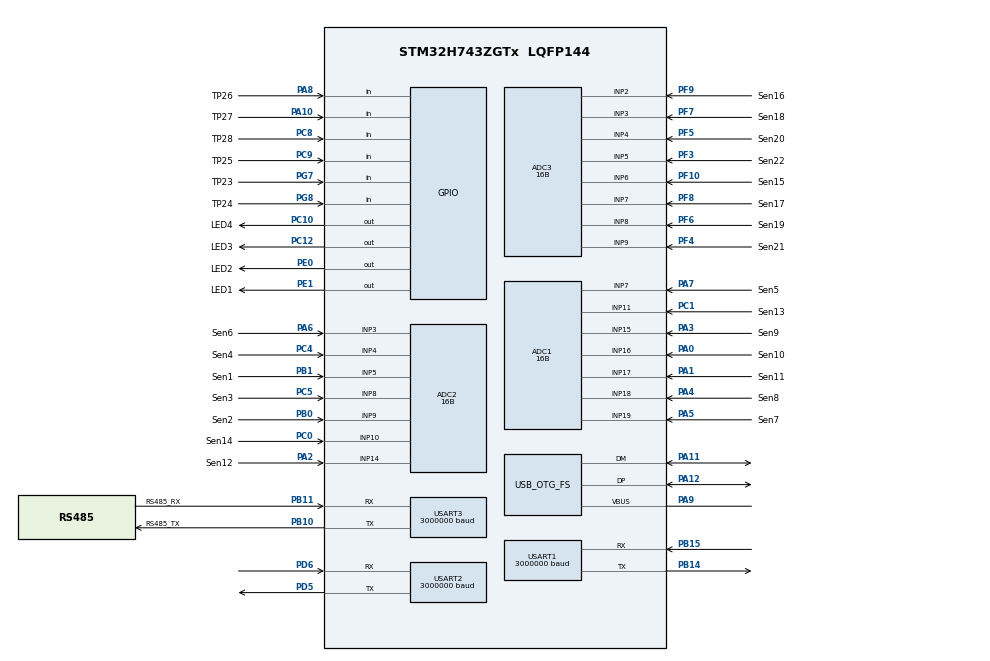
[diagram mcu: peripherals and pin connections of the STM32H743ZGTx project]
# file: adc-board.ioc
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ADC1.Channel-0\#ChannelRegularConversion=ADC_CHANNEL_7
ADC1.Channel-1\#ChannelRegularConversion=ADC_CHANNEL_11
ADC1.Channel-2\#ChannelRegularConversion=ADC_CHANNEL_15
ADC1.Channel-3\#ChannelRegularConversion=ADC_CHANNEL_16
ADC1.Channel-4\#ChannelRegularConversion=ADC_CHANNEL_17
ADC1.Channel-5\#ChannelRegularConversion=ADC_CHANNEL_18
ADC1.Channel-6\#ChannelRegularConversion=ADC_CHANNEL_19
ADC1.ClockPrescaler=ADC_CLOCK_ASYNC_DIV1
ADC1.ContinuousConvMode=DISABLE
ADC1.ConversionDataManagement=ADC_CONVERSIONDATA_DMA_CIRCULAR
ADC1.EOCSelection=ADC_EOC_SEQ_CONV
ADC1.ExternalTrigConv=ADC_EXTERNALTRIG_T1_CC1
ADC1.NbrOfConversion=7
ADC1.NbrOfConversionFlag=1
ADC1.OffsetNumber-0\#ChannelRegularConversion=ADC_OFFSET_NONE
ADC1.OffsetNumber-1\#ChannelRegularConversion=ADC_OFFSET_NONE
ADC1.OffsetNumber-2\#ChannelRegularConversion=ADC_OFFSET_NONE
ADC1.OffsetNumber-3\#ChannelRegularConversion=ADC_OFFSET_NONE
ADC1.OffsetNumber-4\#ChannelRegularConversion=ADC_OFFSET_NONE
ADC1.OffsetNumber-5\#ChannelRegularConversion=ADC_OFFSET_NONE
ADC1.OffsetNumber-6\#ChannelRegularConversion=ADC_OFFSET_NONE
ADC1.OffsetSignedSaturation-0\#ChannelRegularConversion=DISABLE
ADC1.OffsetSignedSaturation-1\#ChannelRegularConversion=DISABLE
ADC1.OffsetSignedSaturation-2\#ChannelRegularConversion=DISABLE
ADC1.OffsetSignedSaturation-3\#ChannelRegularConversion=DISABLE
ADC1.OffsetSignedSaturation-4\#ChannelRegularConversion=DISABLE
ADC1.OffsetSignedSaturation-5\#ChannelRegularConversion=DISABLE
ADC1.OffsetSignedSaturation-6\#ChannelRegularConversion=DISABLE
ADC1.Rank-0\#ChannelRegularConversion=1
ADC1.Rank-1\#ChannelRegularConversion=2
ADC1.Rank-2\#ChannelRegularConversion=3
ADC1.Rank-3\#ChannelRegularConversion=4
ADC1.Rank-4\#ChannelRegularConversion=5
ADC1.Rank-5\#ChannelRegularConversion=6
ADC1.Rank-6\#ChannelRegularConversion=7
ADC1.Resolution=ADC_RESOLUTION_16B
ADC1.SamplingTime-0\#ChannelRegularConversion=ADC_SAMPLETIME_32CYCLES_5
ADC1.SamplingTime-1\#ChannelRegularConversion=ADC_SAMPLETIME_32CYCLES_5
ADC1.SamplingTime-2\#ChannelRegularConversion=ADC_SAMPLETIME_32CYCLES_5
ADC1.SamplingTime-3\#ChannelRegularConversion=ADC_SAMPLETIME_32CYCLES_5
ADC1.SamplingTime-4\#ChannelRegularConversion=ADC_SAMPLETIME_32CYCLES_5
ADC1.SamplingTime-5\#ChannelRegularConversion=ADC_SAMPLETIME_32CYCLES_5
ADC1.SamplingTime-6\#ChannelRegularConversion=ADC_SAMPLETIME_32CYCLES_5
ADC1.master=1
ADC2.Channel-0\#ChannelRegularConversion=ADC_CHANNEL_3
ADC2.Channel-1\#ChannelRegularConversion=ADC_CHANNEL_4
ADC2.Channel-2\#ChannelRegularConversion=ADC_CHANNEL_5
ADC2.Channel-3\#ChannelRegularConversion=ADC_CHANNEL_8
ADC2.Channel-4\#ChannelRegularConversion=ADC_CHANNEL_9
ADC2.Channel-5\#ChannelRegularConversion=ADC_CHANNEL_10
ADC2.Channel-6\#ChannelRegularConversion=ADC_CHANNEL_14
ADC2.ContinuousConvMode=DISABLE
ADC2.ConversionDataManagement=ADC_CONVERSIONDATA_DMA_CIRCULAR
ADC2.EOCSelection=ADC_EOC_SEQ_CONV
ADC2.ExternalTrigConv=ADC_EXTERNALTRIG_T1_CC2
ADC2.ExternalTrigConvEdge=ADC_EXTERNALTRIGCONVEDGE_FALLING
ADC2.NbrOfConversion=7
ADC2.NbrOfConversionFlag=1
ADC2.OffsetNumber-0\#ChannelRegularConversion=ADC_OFFSET_NONE
ADC2.OffsetNumber-1\#ChannelRegularConversion=ADC_OFFSET_NONE
ADC2.OffsetNumber-2\#ChannelRegularConversion=ADC_OFFSET_NONE
ADC2.OffsetNumber-3\#ChannelRegularConversion=ADC_OFFSET_NONE
ADC2.OffsetNumber-4\#ChannelRegularConversion=ADC_OFFSET_NONE
ADC2.OffsetNumber-5\#ChannelRegularConversion=ADC_OFFSET_NONE
ADC2.OffsetNumber-6\#ChannelRegularConversion=ADC_OFFSET_NONE
ADC2.OffsetSignedSaturation-0\#ChannelRegularConversion=DISABLE
ADC2.OffsetSignedSaturation-1\#ChannelRegularConversion=DISABLE
ADC2.OffsetSignedSaturation-2\#ChannelRegularConversion=DISABLE
ADC2.OffsetSignedSaturation-3\#ChannelRegularConversion=DISABLE
ADC2.OffsetSignedSaturation-4\#ChannelRegularConversion=DISABLE
ADC2.OffsetSignedSaturation-5\#ChannelRegularConversion=DISABLE
ADC2.OffsetSignedSaturation-6\#ChannelRegularConversion=DISABLE
ADC2.Rank-0\#ChannelRegularConversion=1
ADC2.Rank-1\#ChannelRegularConversion=2
ADC2.Rank-2\#ChannelRegularConversion=3
ADC2.Rank-3\#ChannelRegularConversion=4
ADC2.Rank-4\#ChannelRegularConversion=5
ADC2.Rank-5\#ChannelRegularConversion=6
ADC2.Rank-6\#ChannelRegularConversion=7
ADC2.Resolution=ADC_RESOLUTION_16B
ADC2.SamplingTime-0\#ChannelRegularConversion=ADC_SAMPLETIME_32CYCLES_5
ADC2.SamplingTime-1\#ChannelRegularConversion=ADC_SAMPLETIME_32CYCLES_5
ADC2.SamplingTime-2\#ChannelRegularConversion=ADC_SAMPLETIME_32CYCLES_5
ADC2.SamplingTime-3\#ChannelRegularConversion=ADC_SAMPLETIME_32CYCLES_5
ADC2.SamplingTime-4\#ChannelRegularConversion=ADC_SAMPLETIME_32CYCLES_5
ADC2.SamplingTime-5\#ChannelRegularConversion=ADC_SAMPLETIME_32CYCLES_5
ADC2.SamplingTime-6\#ChannelRegularConversion=ADC_SAMPLETIME_32CYCLES_5
ADC3.Channel-0\#ChannelRegularConversion=ADC_CHANNEL_2
ADC3.Channel-1\#ChannelRegularConversion=ADC_CHANNEL_3
ADC3.Channel-2\#ChannelRegularConversion=ADC_CHANNEL_4
ADC3.Channel-3\#ChannelRegularConversion=ADC_CHANNEL_5
ADC3.Channel-4\#ChannelRegularConversion=ADC_CHANNEL_6
ADC3.Channel-5\#ChannelRegularConversion=ADC_CHANNEL_7
ADC3.Channel-6\#ChannelRegularConversion=ADC_CHANNEL_8
ADC3.Channel-7\#ChannelRegularConversion=ADC_CHANNEL_9
ADC3.ContinuousConvMode=DISABLE
ADC3.ConversionDataManagement=ADC_CONVERSIONDATA_DMA_CIRCULAR
ADC3.EOCSelection=ADC_EOC_SEQ_CONV
ADC3.ExternalTrigConv=ADC_EXTERNALTRIG_T1_CC3
ADC3.NbrOfConversion=8
ADC3.NbrOfConversionFlag=1
ADC3.OffsetNumber-0\#ChannelRegularConversion=ADC_OFFSET_NONE
ADC3.OffsetNumber-1\#ChannelRegularConversion=ADC_OFFSET_NONE
ADC3.OffsetNumber-2\#ChannelRegularConversion=ADC_OFFSET_NONE
ADC3.OffsetNumber-3\#ChannelRegularConversion=ADC_OFFSET_NONE
ADC3.OffsetNumber-4\#ChannelRegularConversion=ADC_OFFSET_NONE
ADC3.OffsetNumber-5\#ChannelRegularConversion=ADC_OFFSET_NONE
ADC3.OffsetNumber-6\#ChannelRegularConversion=ADC_OFFSET_NONE
ADC3.OffsetNumber-7\#ChannelRegularConversion=ADC_OFFSET_NONE
ADC3.OffsetSignedSaturation-0\#ChannelRegularConversion=DISABLE
ADC3.OffsetSignedSaturation-1\#ChannelRegularConversion=DISABLE
ADC3.OffsetSignedSaturation-2\#ChannelRegularConversion=DISABLE
ADC3.OffsetSignedSaturation-3\#ChannelRegularConversion=DISABLE
ADC3.OffsetSignedSaturation-4\#ChannelRegularConversion=DISABLE
ADC3.OffsetSignedSaturation-5\#ChannelRegularConversion=DISABLE
ADC3.OffsetSignedSaturation-6\#ChannelRegularConversion=DISABLE
ADC3.OffsetSignedSaturation-7\#ChannelRegularConversion=DISABLE
ADC3.OversamplingMode=DISABLE
ADC3.Rank-0\#ChannelRegularConversion=1
ADC3.Rank-1\#ChannelRegularConversion=2
ADC3.Rank-2\#ChannelRegularConversion=3
ADC3.Rank-3\#ChannelRegularConversion=4
ADC3.Rank-4\#ChannelRegularConversion=5
ADC3.Rank-5\#ChannelRegularConversion=6
ADC3.Rank-6\#ChannelRegularConversion=7
ADC3.Rank-7\#ChannelRegularConversion=8
ADC3.Resolution=ADC_RESOLUTION_16B
ADC3.SamplingTime-0\#ChannelRegularConversion=ADC_SAMPLETIME_32CYCLES_5
ADC3.SamplingTime-1\#ChannelRegularConversion=ADC_SAMPLETIME_32CYCLES_5
ADC3.SamplingTime-2\#ChannelRegularConversion=ADC_SAMPLETIME_32CYCLES_5
ADC3.SamplingTime-3\#ChannelRegularConversion=ADC_SAMPLETIME_32CYCLES_5
ADC3.SamplingTime-4\#ChannelRegularConversion=ADC_SAMPLETIME_32CYCLES_5
ADC3.SamplingTime-5\#ChannelRegularConversion=ADC_SAMPLETIME_32CYCLES_5
ADC3.SamplingTime-6\#ChannelRegularConversion=ADC_SAMPLETIME_32CYCLES_5
ADC3.SamplingTime-7\#ChannelRegularConversion=ADC_SAMPLETIME_32CYCLES_5
CORTEX_M7.CPU_DCache=Disabled
CORTEX_M7.CPU_ICache=Enabled
Dma.ADC1.1.Direction=DMA_PERIPH_TO_MEMORY
Dma.ADC1.1.EventEnable=DISABLE
Dma.ADC1.1.FIFOMode=DMA_FIFOMODE_DISABLE
Dma.ADC1.1.Instance=DMA2_Stream0
Dma.ADC1.1.MemDataAlignment=DMA_MDATAALIGN_HALFWORD
Dma.ADC1.1.MemInc=DMA_MINC_ENABLE
Dma.ADC1.1.Mode=DMA_CIRCULAR
Dma.ADC1.1.PeriphDataAlignment=DMA_PDATAALIGN_HALFWORD
Dma.ADC1.1.PeriphInc=DMA_PINC_DISABLE
Dma.ADC1.1.Polarity=HAL_DMAMUX_REQ_GEN_RISING
Dma.ADC1.1.Priority=DMA_PRIORITY_HIGH
Dma.ADC1.1.RequestNumber=1
Dma.ADC1.1.SignalID=NONE
Dma.ADC1.1.SyncEnable=DISABLE
Dma.ADC1.1.SyncPolarity=HAL_DMAMUX_SYNC_NO_EVENT
Dma.ADC1.1.SyncRequestNumber=1
Dma.ADC1.1.SyncSignalID=NONE
Dma.ADC2.2.Direction=DMA_PERIPH_TO_MEMORY
Dma.ADC2.2.EventEnable=DISABLE
Dma.ADC2.2.FIFOMode=DMA_FIFOMODE_DISABLE
Dma.ADC2.2.Instance=DMA2_Stream1
Dma.ADC2.2.MemDataAlignment=DMA_MDATAALIGN_HALFWORD
Dma.ADC2.2.MemInc=DMA_MINC_ENABLE
Dma.ADC2.2.Mode=DMA_CIRCULAR
Dma.ADC2.2.PeriphDataAlignment=DMA_PDATAALIGN_HALFWORD
Dma.ADC2.2.PeriphInc=DMA_PINC_DISABLE
Dma.ADC2.2.Polarity=HAL_DMAMUX_REQ_GEN_RISING
Dma.ADC2.2.Priority=DMA_PRIORITY_HIGH
Dma.ADC2.2.RequestNumber=1
Dma.ADC2.2.SignalID=NONE
Dma.ADC2.2.SyncEnable=DISABLE
Dma.ADC2.2.SyncPolarity=HAL_DMAMUX_SYNC_NO_EVENT
Dma.ADC2.2.SyncRequestNumber=1
Dma.ADC2.2.SyncSignalID=NONE
Dma.ADC3.0.Direction=DMA_PERIPH_TO_MEMORY
Dma.ADC3.0.EventEnable=DISABLE
Dma.ADC3.0.FIFOMode=DMA_FIFOMODE_DISABLE
Dma.ADC3.0.Instance=DMA1_Stream0
Dma.ADC3.0.MemDataAlignment=DMA_MDATAALIGN_HALFWORD
Dma.ADC3.0.MemInc=DMA_MINC_ENABLE
Dma.ADC3.0.Mode=DMA_CIRCULAR
Dma.ADC3.0.PeriphDataAlignment=DMA_PDATAALIGN_HALFWORD
Dma.ADC3.0.PeriphInc=DMA_PINC_DISABLE
Dma.ADC3.0.Polarity=HAL_DMAMUX_REQ_GEN_RISING
Dma.ADC3.0.Priority=DMA_PRIORITY_HIGH
Dma.ADC3.0.RequestNumber=1
Dma.ADC3.0.SignalID=NONE
Dma.ADC3.0.SyncEnable=DISABLE
Dma.ADC3.0.SyncPolarity=HAL_DMAMUX_SYNC_NO_EVENT
Dma.ADC3.0.SyncRequestNumber=1
Dma.ADC3.0.SyncSignalID=NONE
Dma.Request0=ADC3
Dma.Request1=ADC1
Dma.Request2=ADC2
Dma.Request3=USART3_RX
Dma.Request4=USART3_TX
Dma.USART3_RX.3.Direction=DMA_PERIPH_TO_MEMORY
Dma.USART3_RX.3.EventEnable=DISABLE
Dma.USART3_RX.3.FIFOMode=DMA_FIFOMODE_DISABLE
Dma.USART3_RX.3.Instance=DMA1_Stream1
Dma.USART3_RX.3.MemDataAlignment=DMA_MDATAALIGN_BYTE
Dma.USART3_RX.3.MemInc=DMA_MINC_ENABLE
Dma.USART3_RX.3.Mode=DMA_CIRCULAR
Dma.USART3_RX.3.PeriphDataAlignment=DMA_PDATAALIGN_BYTE
Dma.USART3_RX.3.PeriphInc=DMA_PINC_DISABLE
Dma.USART3_RX.3.Polarity=HAL_DMAMUX_REQ_GEN_RISING
Dma.USART3_RX.3.Priority=DMA_PRIORITY_LOW
Dma.USART3_RX.3.RequestNumber=1
Dma.USART3_RX.3.SignalID=NONE
Dma.USART3_RX.3.SyncEnable=DISABLE
Dma.USART3_RX.3.SyncPolarity=HAL_DMAMUX_SYNC_NO_EVENT
Dma.USART3_RX.3.SyncRequestNumber=1
Dma.USART3_RX.3.SyncSignalID=NONE
Dma.USART3_TX.4.Direction=DMA_MEMORY_TO_PERIPH
Dma.USART3_TX.4.EventEnable=DISABLE
Dma.USART3_TX.4.FIFOMode=DMA_FIFOMODE_DISABLE
Dma.USART3_TX.4.Instance=DMA1_Stream2
Dma.USART3_TX.4.MemDataAlignment=DMA_MDATAALIGN_BYTE
Dma.USART3_TX.4.MemInc=DMA_MINC_ENABLE
Dma.USART3_TX.4.Mode=DMA_NORMAL
Dma.USART3_TX.4.PeriphDataAlignment=DMA_PDATAALIGN_BYTE
Dma.USART3_TX.4.PeriphInc=DMA_PINC_DISABLE
Dma.USART3_TX.4.Polarity=HAL_DMAMUX_REQ_GEN_RISING
Dma.USART3_TX.4.Priority=DMA_PRIORITY_MEDIUM
Dma.USART3_TX.4.RequestNumber=1
Dma.USART3_TX.4.SignalID=NONE
Dma.USART3_TX.4.SyncEnable=DISABLE
Dma.USART3_TX.4.SyncPolarity=HAL_DMAMUX_SYNC_NO_EVENT
Dma.USART3_TX.4.SyncRequestNumber=1
Dma.USART3_TX.4.SyncSignalID=NONE
Mcu.Family=STM32H7
Mcu.Name=STM32H743ZGTx
Mcu.Package=LQFP144
NVIC.DMA1_Stream0_IRQn=true\:1\:0\:true\:false\:true\:false\:true
NVIC.DMA1_Stream1_IRQn=true\:0\:0\:false\:false\:true\:false\:true
NVIC.DMA1_Stream2_IRQn=true\:0\:0\:false\:false\:true\:false\:true
NVIC.DMA2_Stream0_IRQn=true\:1\:0\:true\:false\:true\:false\:true
NVIC.DMA2_Stream1_IRQn=true\:1\:0\:true\:false\:true\:false\:true
NVIC.OTG_FS_IRQn=true\:15\:0\:true\:false\:true\:false\:true
NVIC.PriorityGroup=NVIC_PRIORITYGROUP_4
NVIC.TIM1_UP_IRQn=true\:0\:0\:false\:false\:true\:true\:true
NVIC.USART1_IRQn=true\:13\:0\:true\:false\:true\:true\:true
NVIC.USART2_IRQn=true\:14\:0\:true\:false\:true\:true\:true
NVIC.USART3_IRQn=true\:14\:0\:true\:false\:true\:true\:true
PA0.GPIO_Label=Sen10
PA0.Mode=IN16-Single-Ended
PA0.Signal=ADC1_INP16
PA1.GPIO_Label=Sen11
PA1.Mode=IN17-Single-Ended
PA1.Signal=ADC1_INP17
PA10.GPIO_Label=TP27
PA10.Signal=GPIO_Input
PA11.Mode=Device_Only
PA11.Signal=USB_OTG_FS_DM
PA12.Mode=Device_Only
PA12.Signal=USB_OTG_FS_DP
PA13\ (JTMS/SWDIO).Mode=JTAG_5_pins
PA13\ (JTMS/SWDIO).Signal=DEBUG_JTMS-SWDIO
PA14\ (JTCK/SWCLK).Mode=JTAG_5_pins
PA14\ (JTCK/SWCLK).Signal=DEBUG_JTCK-SWCLK
PA15\ (JTDI).Mode=JTAG_5_pins
PA15\ (JTDI).Signal=DEBUG_JTDI
PA2.GPIO_Label=Sen12
PA2.Signal=ADCx_INP14
PA3.GPIO_Label=Sen9
PA3.Signal=ADCx_INP15
PA4.GPIO_Label=Sen8
PA4.Signal=ADCx_INP18
PA5.GPIO_Label=Sen7
PA5.Signal=ADCx_INP19
PA6.GPIO_Label=Sen6
PA6.Signal=ADCx_INP3
PA7.GPIO_Label=Sen5
PA7.Signal=ADCx_INP7
PA8.GPIO_Label=TP26
PA8.Signal=GPIO_Input
PA9.Mode=Activate_VBUS
PA9.Signal=USB_OTG_FS_VBUS
PB0.GPIO_Label=Sen2
PB0.Signal=ADCx_INP9
PB1.GPIO_Label=Sen1
PB1.Signal=ADCx_INP5
PB10.GPIO_Label=RS485_TX
PB10.Mode=Asynchronous
PB10.Signal=USART3_TX
PB11.GPIO_Label=RS485_RX
PB11.Mode=Asynchronous
PB11.Signal=USART3_RX
PB14.Mode=Asynchronous
PB14.Signal=USART1_TX
PB15.Mode=Asynchronous
PB15.Signal=USART1_RX
PB3\ (JTDO/TRACESWO).Mode=JTAG_5_pins
PB3\ (JTDO/TRACESWO).Signal=DEBUG_JTDO-SWO
PB4\ (NJTRST).Mode=JTAG_5_pins
PB4\ (NJTRST).Signal=DEBUG_JTRST
PC0.GPIO_Label=Sen14
PC0.Signal=ADCx_INP10
PC1.GPIO_Label=Sen13
PC1.Signal=ADCx_INP11
PC10.GPIO_Label=LED4
PC10.PinState=GPIO_PIN_SET
PC10.Signal=GPIO_Output
PC12.GPIO_Label=LED3
PC12.Signal=GPIO_Output
PC4.GPIO_Label=Sen4
PC4.Signal=ADCx_INP4
PC5.GPIO_Label=Sen3
PC5.Signal=ADCx_INP8
PC8.GPIO_Label=TP28
PC8.Signal=GPIO_Input
PC9.GPIO_Label=TP25
PC9.Signal=GPIO_Input
PD5.Mode=Asynchronous
PD5.Signal=USART2_TX
PD6.Mode=Asynchronous
PD6.Signal=USART2_RX
PE0.GPIO_Label=LED2
PE0.Signal=GPIO_Output
PE1.GPIO_Label=LED1
PE1.Signal=GPIO_Output
PF10.GPIO_Label=Sen15
PF10.Mode=IN6-Single-Ended
PF10.Signal=ADC3_INP6
PF3.GPIO_Label=Sen22
PF3.Mode=IN5-Single-Ended
PF3.Signal=ADC3_INP5
PF4.GPIO_Label=Sen21
PF4.Mode=IN9-Single-Ended
PF4.Signal=ADC3_INP9
PF5.GPIO_Label=Sen20
PF5.Mode=IN4-Single-Ended
PF5.Signal=ADC3_INP4
PF6.GPIO_Label=Sen19
PF6.Mode=IN8-Single-Ended
PF6.Signal=ADC3_INP8
PF7.GPIO_Label=Sen18
PF7.Mode=IN3-Single-Ended
PF7.Signal=ADC3_INP3
PF8.GPIO_Label=Sen17
PF8.Mode=IN7-Single-Ended
PF8.Signal=ADC3_INP7
PF9.GPIO_Label=Sen16
PF9.Mode=IN2-Single-Ended
PF9.Signal=ADC3_INP2
PG7.GPIO_Label=TP23
PG7.Signal=GPIO_Input
PG8.GPIO_Label=TP24
PG8.Signal=GPIO_Input
ProjectManager.HeapSize=0x200
ProjectManager.StackSize=0x400
ProjectManager.TargetToolchain=STM32CubeIDE
RCC.ADCFreq_Value=120000000
RCC.APB1Freq_Value=120000000
RCC.APB2Freq_Value=120000000
RCC.APB3Freq_Value=120000000
RCC.APB4Freq_Value=120000000
RCC.CortexFreq_Value=60000000
RCC.Cortex_Div=SYSTICK_CLKSOURCE_HCLK_DIV8
RCC.D1PPRE=RCC_APB3_DIV2
RCC.D2PPRE1=RCC_APB1_DIV2
RCC.D2PPRE2=RCC_APB2_DIV2
RCC.D3PPRE=RCC_APB4_DIV2
RCC.DIVM1=8
RCC.DIVM2=4
RCC.DIVM3=4
RCC.DIVN1=120
RCC.DIVN2=30
RCC.DIVN3=48
RCC.DIVP2=4
RCC.DIVQ1=5
RCC.DIVQ2=16
RCC.DIVQ3=8
RCC.DIVR3=6
RCC.HCLKFreq_Value=240000000
RCC.HPRE=RCC_HCLK_DIV2
RCC.HSE_VALUE=8000000
RCC.PLL2FRACN=0
RCC.PLLFRACN=0
RCC.SYSCLKFreq_VALUE=480000000
RCC.SYSCLKSource=RCC_SYSCLKSOURCE_PLLCLK
RCC.USART16CLockSelection=RCC_USART16CLKSOURCE_PLL3
RCC.USART234578CLockSelection=RCC_USART234578CLKSOURCE_PLL3
RCC.USBCLockSelection=RCC_USBCLKSOURCE_HSI48
RCC.USBFreq_Value=48000000
SH.ADCx_INP10.0=ADC2_INP10,IN10-Single-Ended
SH.ADCx_INP11.0=ADC1_INP11,IN11-Single-Ended
SH.ADCx_INP14.0=ADC2_INP14,IN14-Single-Ended
SH.ADCx_INP15.0=ADC1_INP15,IN15-Single-Ended
SH.ADCx_INP18.0=ADC1_INP18,IN18-Single-Ended
SH.ADCx_INP19.0=ADC1_INP19,IN19-Single-Ended
SH.ADCx_INP3.0=ADC2_INP3,IN3-Single-Ended
SH.ADCx_INP4.0=ADC2_INP4,IN4-Single-Ended
SH.ADCx_INP5.0=ADC2_INP5,IN5-Single-Ended
SH.ADCx_INP7.0=ADC1_INP7,IN7-Single-Ended
SH.ADCx_INP8.0=ADC2_INP8,IN8-Single-Ended
SH.ADCx_INP9.0=ADC2_INP9,IN9-Single-Ended
TIM1.AutoReloadPreload=TIM_AUTORELOAD_PRELOAD_ENABLE
TIM1.Channel-Output\ Compare4\ No\ Output=TIM_CHANNEL_4
TIM1.Channel-PWM\ Generation1\ No\ Output=TIM_CHANNEL_1
TIM1.Channel-PWM\ Generation2\ No\ Output=TIM_CHANNEL_2
TIM1.Channel-PWM\ Generation3\ No\ Output=TIM_CHANNEL_3
TIM1.Period=5999
TIM1.Prescaler=1
TIM1.Pulse-Output\ Compare4\ No\ Output=0
TIM1.Pulse-PWM\ Generation1\ No\ Output=1
TIM1.Pulse-PWM\ Generation2\ No\ Output=2000
TIM1.Pulse-PWM\ Generation3\ No\ Output=4000
TIM1.TIM_MasterOutputTrigger=TIM_TRGO_OC4REF
TIM1.TIM_MasterOutputTrigger2=TIM_TRGO2_RESET
USART1.BaudRate=3000000
USART1.FIFOMode=FIFOMODE_ENABLE
USART1.VirtualMode-Asynchronous=VM_ASYNC
USART2.BaudRate=3000000
USART2.FIFOMode=FIFOMODE_ENABLE
USART2.VirtualMode-Asynchronous=VM_ASYNC
USART3.BaudRate=3000000
USART3.FIFOMode=FIFOMODE_ENABLE
USART3.VirtualMode-Asynchronous=VM_ASYNC
USB_DEVICE.CLASS_NAME_FS=CDC
USB_DEVICE.VirtualMode-CDC_FS=Cdc
USB_DEVICE.VirtualModeFS=Cdc_FS
USB_OTG_FS.VirtualMode=Device_Only
USB_OTG_FS.battery_charging_enable=DISABLE
VP_RCC_USB.Mode=USB_FS
VP_TIM1_VS_ClockSourceINT.Mode=Internal
VP_TIM1_VS_no_output1.Mode=PWM Generation1 No Output
VP_TIM1_VS_no_output2.Mode=PWM Generation2 No Output
VP_TIM1_VS_no_output3.Mode=PWM Generation3 No Output
VP_TIM1_VS_no_output4.Mode=Output Compare4 No Output
VP_USB_DEVICE_VS_USB_DEVICE_CDC_FS.Mode=CDC_FS
VP_VREFBUF_V_VREFBUF.Mode=ExternalMode
board=custom

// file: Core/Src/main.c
/* USER CODE BEGIN Header */
/**
  ******************************************************************************
  * @file           : main.c
  * @brief          : Main program body
  ******************************************************************************
  * @attention
  *
  * <h2><center>&copy; Copyright (c) 2020 STMicroelectronics.
  * All rights reserved.</center></h2>
  *
  * This software component is licensed by ST under Ultimate Liberty license
  * SLA0044, the "License"; You may not use this file except in compliance with
  * the License. You may obtain a copy of the License at:
  *                             www.st.com/SLA0044
  *
  ******************************************************************************
  */
/* USER CODE END Header */
#include "main.h"
#include "usb_device.h"

/* USER CODE BEGIN Includes */
//#include "usbd_cdc_if.h"
#include "hdlc.h"
/* USER CODE END Includes */

ADC_HandleTypeDef hadc1;
ADC_HandleTypeDef hadc2;
ADC_HandleTypeDef hadc3;
DMA_HandleTypeDef hdma_adc1;
DMA_HandleTypeDef hdma_adc2;
DMA_HandleTypeDef hdma_adc3;

TIM_HandleTypeDef htim1;

UART_HandleTypeDef huart1;
UART_HandleTypeDef huart2;
UART_HandleTypeDef huart3;
DMA_HandleTypeDef hdma_usart3_rx;
DMA_HandleTypeDef hdma_usart3_tx;

void SystemClock_Config(void);
void PeriphCommonClock_Config(void);
static void MX_GPIO_Init(void);
static void MX_DMA_Init(void);
static void MX_ADC1_Init(void);
static void MX_ADC2_Init(void);
static void MX_ADC3_Init(void);
static void MX_USART1_UART_Init(void);
static void MX_USART3_UART_Init(void);
static void MX_USART2_UART_Init(void);
static void MX_TIM1_Init(void);

/* USER CODE BEGIN 0 */

// important stuff in here!
struct systemstatus status;

// we should compute sample_rate from the clock
// and timer configuration.
uint32_t sample_rate = 20000;

// Our DMA buffer is DMASIZE samples deep, and we don't get an interrupt
// until it is full. So when it is >1, we only run our DSP every that many
// samples. No samples are dropped! We just don't process every time.
#define DMASIZE 2

// Instruct the compiler to align these to cache-line boundaries
// They'll always be read/written as blocks, independently from
// the others, or anything else.
// We also move them into the .dmabuffers section, which is the
// only thing in RAM_D3, so as to minimize contention between
// DMA copying the ADC values into RAM, and everything else we do.
__attribute__ ((aligned (32))) __attribute__(( section(".dmabuffers") )) uint16_t adc1_buffer[7*DMASIZE];
// adc2 drops some DMAs here and there.
__attribute__ ((aligned (32))) __attribute__(( section(".dmabuffers") )) uint16_t adc2_buffer[7*DMASIZE];
__attribute__ ((aligned (32))) __attribute__(( section(".dmabuffers") )) uint16_t adc3_buffer[8*DMASIZE];

// Represents what we need to know for a sensor.
// Values in here should only be altered by external
// configuration processes.
// updates to this structure should be done as atomically
// as possible. prepare a new copy on the stack, disable
// interrupts, bcopy into this array, and reenable.
// TODO get this stored in DTCM
struct sensorconf {
	// True means we're watching a hammer; rises only
	_Bool hammer;
	// Hammer stuff
	// absolute position must be above this to trigger derivative calculations
	// that's a prereq for a note to occur. it should, ideally, be between
	// "impact" and the let off point.
	float minpos;

	// Key stick stuff
	int hammerchan; // corresponding hammer
	float offpos;     // reading at which to trip to off
} conf[22];

struct sensorstate {
	uint32_t notesent; // 0=nothing sent recently, otherwise time of send
	float sentval; // the velocity we sent.
	_Bool damperup;
	_Bool notesounding; // we've sent a noteon, and haven't yet sent a noteoff for it
} state[22];

uint16_t collectstats = 0;
struct sensorstat {
	uint16_t min;
	uint16_t max;
	uint32_t sum;
	uint32_t count;
} stats[22];

struct __attribute__((__packed__)) sensortrip {
	float velocity;
	uint8_t chan;
};

#define BUFSIZE 32
// TODO move these into DTCM
int bufferptrs[3] = { 0 }; // points to the locations we'll write to next. one past the most recent value.
float sensorbuffer[22][BUFSIZE] = { 0.0 };
float derivs[22][3] = { 0.0 } ;
int derividxs[22] = { 0 };

#define FIR_LEN 13
// TODO want this in DTCM also
// scipy.signal.savgol_coeffs(13, 2, deriv=1, use='dot', delta=0.01)
// the delta doesn't matter, so it was chosen to bring the values to ~1.0
float filter[FIR_LEN] = { -3.2967032967033107, -2.7472527472527473,
		-2.197802197802188, -1.64835164835163, -1.0989010989010746,
		-0.5494505494505213, 2.9531932455029164e-14, 0.5494505494505779,
		1.098901098901124, 1.6483516483516676, 2.1978021978022086,
		2.7472527472527473, 3.296703296703284 };
// supposedly argerich can play 11.52 notes/second
// 16000 samples per second. let's leave her some room,
// and assume 16 notes/second. 16000/16 = 1000
#define MINCYCLESBETWEENNOTES 500

_Bool update_setting(uint8_t channel, uint8_t setting, uint32_t value)
{
	if(channel<0 || channel>=22) {
		return 0;
	}
	switch(setting) {
	case 0: {
		// channel type
		if(value==0 || value==1) {
			conf[channel].hammer = value;
			return 1;
		}
		break;
	}
	case 1: {
		// hammer minpos
		float v = *((float *)&value);
		if(conf[channel].hammer && v>1.0 && v<65535.0) {
			conf[channel].minpos = v;
			return 1;
		}
		break;
	}
	case 2: {
		// damper off pos
		float v = *((float *)&value);
		if((!conf[channel].hammer) && v>1.0 && v<65535.0) {
			conf[channel].offpos = v;
			return 1;
		}
		break;
	}
	case 3: {
		// hammer channel for this dampener
		if(conf[channel].hammer)
			// channel is a hammer, not a dampener, can't set this.
			return 0;
		if(value<0 || value>=22)
			// channel out of range
			return 0;
		if(!conf[value].hammer)
			// target channel isn't a hammer!
			return 0;
		conf[channel].hammerchan = value;
		return 1;
	}
	}

	// couldn't successfully process whatever it was.
	return 0;
}

/* USER CODE END 0 */

int main(void)
{

  /* Enable I-Cache---------------------------------------------------------*/
  SCB_EnableICache();

  /* MCU Configuration--------------------------------------------------------*/

  /* Reset of all peripherals, Initializes the Flash interface and the Systick. */
  HAL_Init();

  /* Configure the system clock */
  SystemClock_Config();

/* Configure the peripherals common clocks */
  PeriphCommonClock_Config();

  /* Initialize all configured peripherals */
  MX_GPIO_Init();
  MX_DMA_Init();
  MX_ADC1_Init();
  MX_ADC2_Init();
  MX_ADC3_Init();
  MX_USART1_UART_Init();
  MX_USART3_UART_Init();
  MX_USART2_UART_Init();
  MX_USB_DEVICE_Init();
  MX_TIM1_Init();
  /* USER CODE BEGIN 2 */

  HDLC_Init(&huart3, &hdma_usart3_rx);

  // put some plausible values in the autodetection routines.
  // and get the state initialized.
  for(int i=0; i<22; i++) {
	  // hammer default
	  conf[i].minpos = 15000;

	  // keystick default
	  conf[i].offpos = 9000;

	  state[i].notesent = 0;
	  state[i].sentval = 0.0;
	  state[i].damperup = 0;
	  state[i].notesounding = 0;
  }
  // the hammers
  conf[0].hammer = 1;
  conf[1].hammer = 1;
  conf[2].hammer = 1;
  conf[4].hammer = 1;
  conf[6].hammer = 1;
  conf[9].minpos = 20000;
  conf[9].hammer = 1;
  conf[10].hammer = 1;
  conf[18].hammer = 1;
  conf[18].minpos = 12000;
  conf[19].hammer = 1;
  conf[20].hammer = 1;
  conf[21].hammer = 1;
  // key sticks
  conf[3].hammerchan = 2;
  conf[5].hammerchan = 6;
  conf[5].offpos = 5000;
  conf[7].hammerchan = 0;
  conf[7].offpos = 5000;
  conf[8].hammerchan = 10;
  conf[11].hammerchan = 9;
  conf[11].offpos = 5000;
  conf[12].hammerchan = 1;
  conf[13].hammerchan = 4;
  conf[13].offpos = 5000;
  conf[14].hammerchan = 18;
  conf[15].hammerchan = 19;
  conf[16].hammerchan = 20;
  conf[17].hammerchan = 21;

  HAL_Delay(10);
  HAL_ADCEx_Calibration_Start(&hadc1, ADC_CALIB_OFFSET, ADC_SINGLE_ENDED);
  HAL_Delay(10);
  HAL_ADCEx_Calibration_Start(&hadc2, ADC_CALIB_OFFSET, ADC_SINGLE_ENDED);
  HAL_Delay(10);
  HAL_ADCEx_Calibration_Start(&hadc3, ADC_CALIB_OFFSET, ADC_SINGLE_ENDED);
  HAL_Delay(10);

  {
	  // fill out / initialize the system status struct
	  status.uniqueid[0] = HAL_GetUIDw0();
	  status.uniqueid[1] = HAL_GetUIDw1();
	  status.uniqueid[2] = HAL_GetUIDw2();
	  status.devid = HAL_GetDEVID();
	  status.revid = HAL_GetREVID();
	  // derived this expression from the code for HAL_GetUIDw0
	  status.flashsize = READ_REG(*((uint32_t *)FLASHSIZE_BASE));

	  // this one is actually important, we use it in places
	  status.sample_time = 0;
	  status.adc1_dmas = 0;
	  status.adc2_dmas = 0;
	  status.adc3_dmas = 0;
  }

  HDLC_Send_Frame(&huart3, 0x03, "calibdone", 9);
  HDLC_Send_Frame(&huart3, 0x03, "calibdone", 9);
  HDLC_Send_Frame(&huart3, 0x03, "calibdone", 9);

  HAL_TIM_Base_Start_IT(&htim1);

  // start timer
  HAL_ADC_Start_DMA(&hadc1, (uint32_t*)adc1_buffer, 7*DMASIZE);
  HAL_ADC_Start_DMA(&hadc2, (uint32_t*)adc2_buffer, 7*DMASIZE);
  HAL_ADC_Start_DMA(&hadc3, (uint32_t*)adc3_buffer, 8*DMASIZE);
  HAL_TIM_PWM_Start(&htim1, TIM_CHANNEL_1);
  HAL_TIM_PWM_Start(&htim1, TIM_CHANNEL_2);
  HAL_TIM_PWM_Start(&htim1, TIM_CHANNEL_3);
  HAL_TIM_OC_Start(&htim1, TIM_CHANNEL_4);

  /* USER CODE END 2 */

  /* Infinite loop */
  /* USER CODE BEGIN WHILE */

  uint32_t last_clock_pulse = 1<<30;
  while (1)
  {
	  // we'll wake up occasionally.
	  __asm("wfi");

	  // how much time has passed since our last clock message?
	  // if(lots) { output new clock message }
	  uint32_t clock_rate = sample_rate * 64; // 64 seconds; should be a bitshift
	  if(  ((status.sample_time < last_clock_pulse) &&
		    ((UINT32_MAX - last_clock_pulse) + status.sample_time >= clock_rate))
		|| ((status.sample_time > last_clock_pulse) &&
			(status.sample_time - last_clock_pulse >= clock_rate)) ) {
		  // we've passed clock_rate worth of samples, so we'll send another clock message
		  HDLC_Send_Frame(&huart3, 0x07, (uint8_t*)&(status.sample_time), sizeof(uint32_t));
		  last_clock_pulse = status.sample_time;
	  }

	  if(collectstats) {
		  if((status.sample_time % collectstats)==0) {
			  // we should be collecting stats. send them out.
			  HDLC_Send_Frame(&huart3, 0x0C, (uint8_t*)stats, sizeof(stats));
			  for(int i=0; i<22; i++) {
				  stats[i].min = -1;
				  stats[i].max = 0;
				  stats[i].sum = 0;
				  stats[i].count = 0;
			  }
		  }
	  }

    /* USER CODE END WHILE */

  }
}

void SystemClock_Config(void)
{
  RCC_OscInitTypeDef RCC_OscInitStruct = {0};
  RCC_ClkInitTypeDef RCC_ClkInitStruct = {0};
  RCC_CRSInitTypeDef RCC_CRSInitStruct = {0};

  /** Supply configuration update enable
  */
  HAL_PWREx_ConfigSupply(PWR_LDO_SUPPLY);
  /** Configure the main internal regulator output voltage
  */
  __HAL_PWR_VOLTAGESCALING_CONFIG(PWR_REGULATOR_VOLTAGE_SCALE0);

  while(!__HAL_PWR_GET_FLAG(PWR_FLAG_VOSRDY)) {}
  /** Macro to configure the PLL clock source
  */
  __HAL_RCC_PLL_PLLSOURCE_CONFIG(RCC_PLLSOURCE_HSI);
  /** Initializes the RCC Oscillators according to the specified parameters
  * in the RCC_OscInitTypeDef structure.
  */
  RCC_OscInitStruct.OscillatorType = RCC_OSCILLATORTYPE_HSI48|RCC_OSCILLATORTYPE_HSI;
  RCC_OscInitStruct.HSIState = RCC_HSI_DIV1;
  RCC_OscInitStruct.HSICalibrationValue = RCC_HSICALIBRATION_DEFAULT;
  RCC_OscInitStruct.HSI48State = RCC_HSI48_ON;
  RCC_OscInitStruct.PLL.PLLState = RCC_PLL_ON;
  RCC_OscInitStruct.PLL.PLLSource = RCC_PLLSOURCE_HSI;
  RCC_OscInitStruct.PLL.PLLM = 8;
  RCC_OscInitStruct.PLL.PLLN = 120;
  RCC_OscInitStruct.PLL.PLLP = 2;
  RCC_OscInitStruct.PLL.PLLQ = 5;
  RCC_OscInitStruct.PLL.PLLR = 2;
  RCC_OscInitStruct.PLL.PLLRGE = RCC_PLL1VCIRANGE_3;
  RCC_OscInitStruct.PLL.PLLVCOSEL = RCC_PLL1VCOWIDE;
  RCC_OscInitStruct.PLL.PLLFRACN = 0;
  if (HAL_RCC_OscConfig(&RCC_OscInitStruct) != HAL_OK)
  {
    Error_Handler();
  }
  /** Initializes the CPU, AHB and APB buses clocks
  */
  RCC_ClkInitStruct.ClockType = RCC_CLOCKTYPE_HCLK|RCC_CLOCKTYPE_SYSCLK
                              |RCC_CLOCKTYPE_PCLK1|RCC_CLOCKTYPE_PCLK2
                              |RCC_CLOCKTYPE_D3PCLK1|RCC_CLOCKTYPE_D1PCLK1;
  RCC_ClkInitStruct.SYSCLKSource = RCC_SYSCLKSOURCE_PLLCLK;
  RCC_ClkInitStruct.SYSCLKDivider = RCC_SYSCLK_DIV1;
  RCC_ClkInitStruct.AHBCLKDivider = RCC_HCLK_DIV2;
  RCC_ClkInitStruct.APB3CLKDivider = RCC_APB3_DIV2;
  RCC_ClkInitStruct.APB1CLKDivider = RCC_APB1_DIV2;
  RCC_ClkInitStruct.APB2CLKDivider = RCC_APB2_DIV2;
  RCC_ClkInitStruct.APB4CLKDivider = RCC_APB4_DIV2;

  if (HAL_RCC_ClockConfig(&RCC_ClkInitStruct, FLASH_LATENCY_4) != HAL_OK)
  {
    Error_Handler();
  }
  /** Enable the SYSCFG APB clock
  */
  __HAL_RCC_CRS_CLK_ENABLE();
  /** Configures CRS
  */
  RCC_CRSInitStruct.Prescaler = RCC_CRS_SYNC_DIV1;
  RCC_CRSInitStruct.Source = RCC_CRS_SYNC_SOURCE_USB2;
  RCC_CRSInitStruct.Polarity = RCC_CRS_SYNC_POLARITY_RISING;
  RCC_CRSInitStruct.ReloadValue = __HAL_RCC_CRS_RELOADVALUE_CALCULATE(48000000,1000);
  RCC_CRSInitStruct.ErrorLimitValue = 34;
  RCC_CRSInitStruct.HSI48CalibrationValue = 32;

  HAL_RCCEx_CRSConfig(&RCC_CRSInitStruct);
}

void PeriphCommonClock_Config(void)
{
  RCC_PeriphCLKInitTypeDef PeriphClkInitStruct = {0};

  /** Initializes the peripherals clock
  */
  PeriphClkInitStruct.PeriphClockSelection = RCC_PERIPHCLK_ADC|RCC_PERIPHCLK_USART1
                              |RCC_PERIPHCLK_USART2|RCC_PERIPHCLK_USART3;
  PeriphClkInitStruct.PLL2.PLL2M = 4;
  PeriphClkInitStruct.PLL2.PLL2N = 30;
  PeriphClkInitStruct.PLL2.PLL2P = 4;
  PeriphClkInitStruct.PLL2.PLL2Q = 16;
  PeriphClkInitStruct.PLL2.PLL2R = 2;
  PeriphClkInitStruct.PLL2.PLL2RGE = RCC_PLL2VCIRANGE_3;
  PeriphClkInitStruct.PLL2.PLL2VCOSEL = RCC_PLL2VCOWIDE;
  PeriphClkInitStruct.PLL2.PLL2FRACN = 0;
  PeriphClkInitStruct.PLL3.PLL3M = 4;
  PeriphClkInitStruct.PLL3.PLL3N = 48;
  PeriphClkInitStruct.PLL3.PLL3P = 2;
  PeriphClkInitStruct.PLL3.PLL3Q = 8;
  PeriphClkInitStruct.PLL3.PLL3R = 6;
  PeriphClkInitStruct.PLL3.PLL3RGE = RCC_PLL3VCIRANGE_3;
  PeriphClkInitStruct.PLL3.PLL3VCOSEL = RCC_PLL3VCOWIDE;
  PeriphClkInitStruct.PLL3.PLL3FRACN = 0;
  PeriphClkInitStruct.Usart234578ClockSelection = RCC_USART234578CLKSOURCE_PLL3;
  PeriphClkInitStruct.Usart16ClockSelection = RCC_USART16CLKSOURCE_PLL3;
  PeriphClkInitStruct.AdcClockSelection = RCC_ADCCLKSOURCE_PLL2;
  if (HAL_RCCEx_PeriphCLKConfig(&PeriphClkInitStruct) != HAL_OK)
  {
    Error_Handler();
  }
}

static void MX_ADC1_Init(void)
{

  ADC_MultiModeTypeDef multimode = {0};
  ADC_ChannelConfTypeDef sConfig = {0};

  /** Common config
  */
  hadc1.Instance = ADC1;
  hadc1.Init.ClockPrescaler = ADC_CLOCK_ASYNC_DIV1;
  hadc1.Init.Resolution = ADC_RESOLUTION_16B;
  hadc1.Init.ScanConvMode = ADC_SCAN_ENABLE;
  hadc1.Init.EOCSelection = ADC_EOC_SEQ_CONV;
  hadc1.Init.LowPowerAutoWait = DISABLE;
  hadc1.Init.ContinuousConvMode = DISABLE;
  hadc1.Init.NbrOfConversion = 7;
  hadc1.Init.DiscontinuousConvMode = DISABLE;
  hadc1.Init.ExternalTrigConv = ADC_EXTERNALTRIG_T1_CC1;
  hadc1.Init.ExternalTrigConvEdge = ADC_EXTERNALTRIGCONVEDGE_RISING;
  hadc1.Init.ConversionDataManagement = ADC_CONVERSIONDATA_DMA_CIRCULAR;
  hadc1.Init.Overrun = ADC_OVR_DATA_PRESERVED;
  hadc1.Init.LeftBitShift = ADC_LEFTBITSHIFT_NONE;
  hadc1.Init.OversamplingMode = DISABLE;
  if (HAL_ADC_Init(&hadc1) != HAL_OK)
  {
    Error_Handler();
  }
  /** Configure the ADC multi-mode
  */
  multimode.Mode = ADC_MODE_INDEPENDENT;
  if (HAL_ADCEx_MultiModeConfigChannel(&hadc1, &multimode) != HAL_OK)
  {
    Error_Handler();
  }
  /** Configure Regular Channel
  */
  sConfig.Channel = ADC_CHANNEL_7;
  sConfig.Rank = ADC_REGULAR_RANK_1;
  sConfig.SamplingTime = ADC_SAMPLETIME_32CYCLES_5;
  sConfig.SingleDiff = ADC_SINGLE_ENDED;
  sConfig.OffsetNumber = ADC_OFFSET_NONE;
  sConfig.Offset = 0;
  sConfig.OffsetSignedSaturation = DISABLE;
  if (HAL_ADC_ConfigChannel(&hadc1, &sConfig) != HAL_OK)
  {
    Error_Handler();
  }
  /** Configure Regular Channel
  */
  sConfig.Channel = ADC_CHANNEL_11;
  sConfig.Rank = ADC_REGULAR_RANK_2;
  if (HAL_ADC_ConfigChannel(&hadc1, &sConfig) != HAL_OK)
  {
    Error_Handler();
  }
  /** Configure Regular Channel
  */
  sConfig.Channel = ADC_CHANNEL_15;
  sConfig.Rank = ADC_REGULAR_RANK_3;
  if (HAL_ADC_ConfigChannel(&hadc1, &sConfig) != HAL_OK)
  {
    Error_Handler();
  }
  /** Configure Regular Channel
  */
  sConfig.Channel = ADC_CHANNEL_16;
  sConfig.Rank = ADC_REGULAR_RANK_4;
  if (HAL_ADC_ConfigChannel(&hadc1, &sConfig) != HAL_OK)
  {
    Error_Handler();
  }
  /** Configure Regular Channel
  */
  sConfig.Channel = ADC_CHANNEL_17;
  sConfig.Rank = ADC_REGULAR_RANK_5;
  if (HAL_ADC_ConfigChannel(&hadc1, &sConfig) != HAL_OK)
  {
    Error_Handler();
  }
  /** Configure Regular Channel
  */
  sConfig.Channel = ADC_CHANNEL_18;
  sConfig.Rank = ADC_REGULAR_RANK_6;
  if (HAL_ADC_ConfigChannel(&hadc1, &sConfig) != HAL_OK)
  {
    Error_Handler();
  }
  /** Configure Regular Channel
  */
  sConfig.Channel = ADC_CHANNEL_19;
  sConfig.Rank = ADC_REGULAR_RANK_7;
  if (HAL_ADC_ConfigChannel(&hadc1, &sConfig) != HAL_OK)
  {
    Error_Handler();
  }

}

static void MX_ADC2_Init(void)
{

  ADC_ChannelConfTypeDef sConfig = {0};

  /** Common config
  */
  hadc2.Instance = ADC2;
  hadc2.Init.ClockPrescaler = ADC_CLOCK_ASYNC_DIV1;
  hadc2.Init.Resolution = ADC_RESOLUTION_16B;
  hadc2.Init.ScanConvMode = ADC_SCAN_ENABLE;
  hadc2.Init.EOCSelection = ADC_EOC_SEQ_CONV;
  hadc2.Init.LowPowerAutoWait = DISABLE;
  hadc2.Init.ContinuousConvMode = DISABLE;
  hadc2.Init.NbrOfConversion = 7;
  hadc2.Init.DiscontinuousConvMode = DISABLE;
  hadc2.Init.ExternalTrigConv = ADC_EXTERNALTRIG_T1_CC2;
  hadc2.Init.ExternalTrigConvEdge = ADC_EXTERNALTRIGCONVEDGE_FALLING;
  hadc2.Init.ConversionDataManagement = ADC_CONVERSIONDATA_DMA_CIRCULAR;
  hadc2.Init.Overrun = ADC_OVR_DATA_PRESERVED;
  hadc2.Init.LeftBitShift = ADC_LEFTBITSHIFT_NONE;
  hadc2.Init.OversamplingMode = DISABLE;
  if (HAL_ADC_Init(&hadc2) != HAL_OK)
  {
    Error_Handler();
  }
  /** Configure Regular Channel
  */
  sConfig.Channel = ADC_CHANNEL_3;
  sConfig.Rank = ADC_REGULAR_RANK_1;
  sConfig.SamplingTime = ADC_SAMPLETIME_32CYCLES_5;
  sConfig.SingleDiff = ADC_SINGLE_ENDED;
  sConfig.OffsetNumber = ADC_OFFSET_NONE;
  sConfig.Offset = 0;
  sConfig.OffsetSignedSaturation = DISABLE;
  if (HAL_ADC_ConfigChannel(&hadc2, &sConfig) != HAL_OK)
  {
    Error_Handler();
  }
  /** Configure Regular Channel
  */
  sConfig.Channel = ADC_CHANNEL_4;
  sConfig.Rank = ADC_REGULAR_RANK_2;
  if (HAL_ADC_ConfigChannel(&hadc2, &sConfig) != HAL_OK)
  {
    Error_Handler();
  }
  /** Configure Regular Channel
  */
  sConfig.Channel = ADC_CHANNEL_5;
  sConfig.Rank = ADC_REGULAR_RANK_3;
  if (HAL_ADC_ConfigChannel(&hadc2, &sConfig) != HAL_OK)
  {
    Error_Handler();
  }
  /** Configure Regular Channel
  */
  sConfig.Channel = ADC_CHANNEL_8;
  sConfig.Rank = ADC_REGULAR_RANK_4;
  if (HAL_ADC_ConfigChannel(&hadc2, &sConfig) != HAL_OK)
  {
    Error_Handler();
  }
  /** Configure Regular Channel
  */
  sConfig.Channel = ADC_CHANNEL_9;
  sConfig.Rank = ADC_REGULAR_RANK_5;
  if (HAL_ADC_ConfigChannel(&hadc2, &sConfig) != HAL_OK)
  {
    Error_Handler();
  }
  /** Configure Regular Channel
  */
  sConfig.Channel = ADC_CHANNEL_10;
  sConfig.Rank = ADC_REGULAR_RANK_6;
  if (HAL_ADC_ConfigChannel(&hadc2, &sConfig) != HAL_OK)
  {
    Error_Handler();
  }
  /** Configure Regular Channel
  */
  sConfig.Channel = ADC_CHANNEL_14;
  sConfig.Rank = ADC_REGULAR_RANK_7;
  if (HAL_ADC_ConfigChannel(&hadc2, &sConfig) != HAL_OK)
  {
    Error_Handler();
  }

}

static void MX_ADC3_Init(void)
{

  ADC_ChannelConfTypeDef sConfig = {0};

  /** Common config
  */
  hadc3.Instance = ADC3;
  hadc3.Init.ClockPrescaler = ADC_CLOCK_ASYNC_DIV1;
  hadc3.Init.Resolution = ADC_RESOLUTION_16B;
  hadc3.Init.ScanConvMode = ADC_SCAN_ENABLE;
  hadc3.Init.EOCSelection = ADC_EOC_SEQ_CONV;
  hadc3.Init.LowPowerAutoWait = DISABLE;
  hadc3.Init.ContinuousConvMode = DISABLE;
  hadc3.Init.NbrOfConversion = 8;
  hadc3.Init.DiscontinuousConvMode = DISABLE;
  hadc3.Init.ExternalTrigConv = ADC_EXTERNALTRIG_T1_CC3;
  hadc3.Init.ExternalTrigConvEdge = ADC_EXTERNALTRIGCONVEDGE_RISING;
  hadc3.Init.ConversionDataManagement = ADC_CONVERSIONDATA_DMA_CIRCULAR;
  hadc3.Init.Overrun = ADC_OVR_DATA_PRESERVED;
  hadc3.Init.LeftBitShift = ADC_LEFTBITSHIFT_NONE;
  hadc3.Init.OversamplingMode = DISABLE;
  if (HAL_ADC_Init(&hadc3) != HAL_OK)
  {
    Error_Handler();
  }
  /** Configure Regular Channel
  */
  sConfig.Channel = ADC_CHANNEL_2;
  sConfig.Rank = ADC_REGULAR_RANK_1;
  sConfig.SamplingTime = ADC_SAMPLETIME_32CYCLES_5;
  sConfig.SingleDiff = ADC_SINGLE_ENDED;
  sConfig.OffsetNumber = ADC_OFFSET_NONE;
  sConfig.Offset = 0;
  sConfig.OffsetSignedSaturation = DISABLE;
  if (HAL_ADC_ConfigChannel(&hadc3, &sConfig) != HAL_OK)
  {
    Error_Handler();
  }
  /** Configure Regular Channel
  */
  sConfig.Channel = ADC_CHANNEL_3;
  sConfig.Rank = ADC_REGULAR_RANK_2;
  if (HAL_ADC_ConfigChannel(&hadc3, &sConfig) != HAL_OK)
  {
    Error_Handler();
  }
  /** Configure Regular Channel
  */
  sConfig.Channel = ADC_CHANNEL_4;
  sConfig.Rank = ADC_REGULAR_RANK_3;
  if (HAL_ADC_ConfigChannel(&hadc3, &sConfig) != HAL_OK)
  {
    Error_Handler();
  }
  /** Configure Regular Channel
  */
  sConfig.Channel = ADC_CHANNEL_5;
  sConfig.Rank = ADC_REGULAR_RANK_4;
  if (HAL_ADC_ConfigChannel(&hadc3, &sConfig) != HAL_OK)
  {
    Error_Handler();
  }
  /** Configure Regular Channel
  */
  sConfig.Channel = ADC_CHANNEL_6;
  sConfig.Rank = ADC_REGULAR_RANK_5;
  if (HAL_ADC_ConfigChannel(&hadc3, &sConfig) != HAL_OK)
  {
    Error_Handler();
  }
  /** Configure Regular Channel
  */
  sConfig.Channel = ADC_CHANNEL_7;
  sConfig.Rank = ADC_REGULAR_RANK_6;
  if (HAL_ADC_ConfigChannel(&hadc3, &sConfig) != HAL_OK)
  {
    Error_Handler();
  }
  /** Configure Regular Channel
  */
  sConfig.Channel = ADC_CHANNEL_8;
  sConfig.Rank = ADC_REGULAR_RANK_7;
  if (HAL_ADC_ConfigChannel(&hadc3, &sConfig) != HAL_OK)
  {
    Error_Handler();
  }
  /** Configure Regular Channel
  */
  sConfig.Channel = ADC_CHANNEL_9;
  sConfig.Rank = ADC_REGULAR_RANK_8;
  if (HAL_ADC_ConfigChannel(&hadc3, &sConfig) != HAL_OK)
  {
    Error_Handler();
  }

}

static void MX_TIM1_Init(void)
{

  TIM_ClockConfigTypeDef sClockSourceConfig = {0};
  TIM_MasterConfigTypeDef sMasterConfig = {0};
  TIM_OC_InitTypeDef sConfigOC = {0};
  TIM_BreakDeadTimeConfigTypeDef sBreakDeadTimeConfig = {0};

  htim1.Instance = TIM1;
  htim1.Init.Prescaler = 1;
  htim1.Init.CounterMode = TIM_COUNTERMODE_UP;
  htim1.Init.Period = 5999;
  htim1.Init.ClockDivision = TIM_CLOCKDIVISION_DIV1;
  htim1.Init.RepetitionCounter = 0;
  htim1.Init.AutoReloadPreload = TIM_AUTORELOAD_PRELOAD_ENABLE;
  if (HAL_TIM_Base_Init(&htim1) != HAL_OK)
  {
    Error_Handler();
  }
  sClockSourceConfig.ClockSource = TIM_CLOCKSOURCE_INTERNAL;
  if (HAL_TIM_ConfigClockSource(&htim1, &sClockSourceConfig) != HAL_OK)
  {
    Error_Handler();
  }
  if (HAL_TIM_PWM_Init(&htim1) != HAL_OK)
  {
    Error_Handler();
  }
  if (HAL_TIM_OC_Init(&htim1) != HAL_OK)
  {
    Error_Handler();
  }
  sMasterConfig.MasterOutputTrigger = TIM_TRGO_OC4REF;
  sMasterConfig.MasterOutputTrigger2 = TIM_TRGO2_RESET;
  sMasterConfig.MasterSlaveMode = TIM_MASTERSLAVEMODE_DISABLE;
  if (HAL_TIMEx_MasterConfigSynchronization(&htim1, &sMasterConfig) != HAL_OK)
  {
    Error_Handler();
  }
  sConfigOC.OCMode = TIM_OCMODE_PWM1;
  sConfigOC.Pulse = 1;
  sConfigOC.OCPolarity = TIM_OCPOLARITY_HIGH;
  sConfigOC.OCNPolarity = TIM_OCNPOLARITY_HIGH;
  sConfigOC.OCFastMode = TIM_OCFAST_DISABLE;
  sConfigOC.OCIdleState = TIM_OCIDLESTATE_RESET;
  sConfigOC.OCNIdleState = TIM_OCNIDLESTATE_RESET;
  if (HAL_TIM_PWM_ConfigChannel(&htim1, &sConfigOC, TIM_CHANNEL_1) != HAL_OK)
  {
    Error_Handler();
  }
  sConfigOC.Pulse = 2000;
  if (HAL_TIM_PWM_ConfigChannel(&htim1, &sConfigOC, TIM_CHANNEL_2) != HAL_OK)
  {
    Error_Handler();
  }
  sConfigOC.Pulse = 4000;
  if (HAL_TIM_PWM_ConfigChannel(&htim1, &sConfigOC, TIM_CHANNEL_3) != HAL_OK)
  {
    Error_Handler();
  }
  sConfigOC.OCMode = TIM_OCMODE_TIMING;
  sConfigOC.Pulse = 0;
  if (HAL_TIM_OC_ConfigChannel(&htim1, &sConfigOC, TIM_CHANNEL_4) != HAL_OK)
  {
    Error_Handler();
  }
  sBreakDeadTimeConfig.OffStateRunMode = TIM_OSSR_DISABLE;
  sBreakDeadTimeConfig.OffStateIDLEMode = TIM_OSSI_DISABLE;
  sBreakDeadTimeConfig.LockLevel = TIM_LOCKLEVEL_OFF;
  sBreakDeadTimeConfig.DeadTime = 0;
  sBreakDeadTimeConfig.BreakState = TIM_BREAK_DISABLE;
  sBreakDeadTimeConfig.BreakPolarity = TIM_BREAKPOLARITY_HIGH;
  sBreakDeadTimeConfig.BreakFilter = 0;
  sBreakDeadTimeConfig.Break2State = TIM_BREAK2_DISABLE;
  sBreakDeadTimeConfig.Break2Polarity = TIM_BREAK2POLARITY_HIGH;
  sBreakDeadTimeConfig.Break2Filter = 0;
  sBreakDeadTimeConfig.AutomaticOutput = TIM_AUTOMATICOUTPUT_DISABLE;
  if (HAL_TIMEx_ConfigBreakDeadTime(&htim1, &sBreakDeadTimeConfig) != HAL_OK)
  {
    Error_Handler();
  }

}

static void MX_USART1_UART_Init(void)
{

  huart1.Instance = USART1;
  huart1.Init.BaudRate = 3000000;
  huart1.Init.WordLength = UART_WORDLENGTH_8B;
  huart1.Init.StopBits = UART_STOPBITS_1;
  huart1.Init.Parity = UART_PARITY_NONE;
  huart1.Init.Mode = UART_MODE_TX_RX;
  huart1.Init.HwFlowCtl = UART_HWCONTROL_NONE;
  huart1.Init.OverSampling = UART_OVERSAMPLING_16;
  huart1.Init.OneBitSampling = UART_ONE_BIT_SAMPLE_DISABLE;
  huart1.Init.ClockPrescaler = UART_PRESCALER_DIV1;
  huart1.AdvancedInit.AdvFeatureInit = UART_ADVFEATURE_NO_INIT;
  if (HAL_UART_Init(&huart1) != HAL_OK)
  {
    Error_Handler();
  }
  if (HAL_UARTEx_SetTxFifoThreshold(&huart1, UART_TXFIFO_THRESHOLD_1_8) != HAL_OK)
  {
    Error_Handler();
  }
  if (HAL_UARTEx_SetRxFifoThreshold(&huart1, UART_RXFIFO_THRESHOLD_1_8) != HAL_OK)
  {
    Error_Handler();
  }
  if (HAL_UARTEx_EnableFifoMode(&huart1) != HAL_OK)
  {
    Error_Handler();
  }

}

static void MX_USART2_UART_Init(void)
{

  huart2.Instance = USART2;
  huart2.Init.BaudRate = 3000000;
  huart2.Init.WordLength = UART_WORDLENGTH_8B;
  huart2.Init.StopBits = UART_STOPBITS_1;
  huart2.Init.Parity = UART_PARITY_NONE;
  huart2.Init.Mode = UART_MODE_TX_RX;
  huart2.Init.HwFlowCtl = UART_HWCONTROL_NONE;
  huart2.Init.OverSampling = UART_OVERSAMPLING_16;
  huart2.Init.OneBitSampling = UART_ONE_BIT_SAMPLE_DISABLE;
  huart2.Init.ClockPrescaler = UART_PRESCALER_DIV1;
  huart2.AdvancedInit.AdvFeatureInit = UART_ADVFEATURE_NO_INIT;
  if (HAL_UART_Init(&huart2) != HAL_OK)
  {
    Error_Handler();
  }
  if (HAL_UARTEx_SetTxFifoThreshold(&huart2, UART_TXFIFO_THRESHOLD_1_8) != HAL_OK)
  {
    Error_Handler();
  }
  if (HAL_UARTEx_SetRxFifoThreshold(&huart2, UART_RXFIFO_THRESHOLD_1_8) != HAL_OK)
  {
    Error_Handler();
  }
  if (HAL_UARTEx_EnableFifoMode(&huart2) != HAL_OK)
  {
    Error_Handler();
  }

}

static void MX_USART3_UART_Init(void)
{

  huart3.Instance = USART3;
  huart3.Init.BaudRate = 3000000;
  huart3.Init.WordLength = UART_WORDLENGTH_8B;
  huart3.Init.StopBits = UART_STOPBITS_1;
  huart3.Init.Parity = UART_PARITY_NONE;
  huart3.Init.Mode = UART_MODE_TX_RX;
  huart3.Init.HwFlowCtl = UART_HWCONTROL_NONE;
  huart3.Init.OverSampling = UART_OVERSAMPLING_16;
  huart3.Init.OneBitSampling = UART_ONE_BIT_SAMPLE_DISABLE;
  huart3.Init.ClockPrescaler = UART_PRESCALER_DIV1;
  huart3.AdvancedInit.AdvFeatureInit = UART_ADVFEATURE_NO_INIT;
  if (HAL_UART_Init(&huart3) != HAL_OK)
  {
    Error_Handler();
  }
  if (HAL_UARTEx_SetTxFifoThreshold(&huart3, UART_TXFIFO_THRESHOLD_1_8) != HAL_OK)
  {
    Error_Handler();
  }
  if (HAL_UARTEx_SetRxFifoThreshold(&huart3, UART_RXFIFO_THRESHOLD_1_8) != HAL_OK)
  {
    Error_Handler();
  }
  if (HAL_UARTEx_EnableFifoMode(&huart3) != HAL_OK)
  {
    Error_Handler();
  }

}

static void MX_DMA_Init(void)
{

  /* DMA controller clock enable */
  __HAL_RCC_DMA1_CLK_ENABLE();
  __HAL_RCC_DMA2_CLK_ENABLE();

  /* DMA interrupt init */
  /* DMA1_Stream0_IRQn interrupt configuration */
  HAL_NVIC_SetPriority(DMA1_Stream0_IRQn, 1, 0);
  HAL_NVIC_EnableIRQ(DMA1_Stream0_IRQn);
  /* DMA1_Stream1_IRQn interrupt configuration */
  HAL_NVIC_SetPriority(DMA1_Stream1_IRQn, 0, 0);
  HAL_NVIC_EnableIRQ(DMA1_Stream1_IRQn);
  /* DMA1_Stream2_IRQn interrupt configuration */
  HAL_NVIC_SetPriority(DMA1_Stream2_IRQn, 0, 0);
  HAL_NVIC_EnableIRQ(DMA1_Stream2_IRQn);
  /* DMA2_Stream0_IRQn interrupt configuration */
  HAL_NVIC_SetPriority(DMA2_Stream0_IRQn, 1, 0);
  HAL_NVIC_EnableIRQ(DMA2_Stream0_IRQn);
  /* DMA2_Stream1_IRQn interrupt configuration */
  HAL_NVIC_SetPriority(DMA2_Stream1_IRQn, 1, 0);
  HAL_NVIC_EnableIRQ(DMA2_Stream1_IRQn);

}

static void MX_GPIO_Init(void)
{
  GPIO_InitTypeDef GPIO_InitStruct = {0};

  /* GPIO Ports Clock Enable */
  __HAL_RCC_GPIOF_CLK_ENABLE();
  __HAL_RCC_GPIOC_CLK_ENABLE();
  __HAL_RCC_GPIOA_CLK_ENABLE();
  __HAL_RCC_GPIOB_CLK_ENABLE();
  __HAL_RCC_GPIOG_CLK_ENABLE();
  __HAL_RCC_GPIOD_CLK_ENABLE();
  __HAL_RCC_GPIOE_CLK_ENABLE();

  /*Configure GPIO pin Output Level */
  HAL_GPIO_WritePin(LED4_GPIO_Port, LED4_Pin, GPIO_PIN_SET);

  /*Configure GPIO pin Output Level */
  HAL_GPIO_WritePin(LED3_GPIO_Port, LED3_Pin, GPIO_PIN_RESET);

  /*Configure GPIO pin Output Level */
  HAL_GPIO_WritePin(GPIOE, LED2_Pin|LED1_Pin, GPIO_PIN_RESET);

  /*Configure GPIO pins : TP23_Pin TP24_Pin */
  GPIO_InitStruct.Pin = TP23_Pin|TP24_Pin;
  GPIO_InitStruct.Mode = GPIO_MODE_INPUT;
  GPIO_InitStruct.Pull = GPIO_NOPULL;
  HAL_GPIO_Init(GPIOG, &GPIO_InitStruct);

  /*Configure GPIO pins : TP28_Pin TP25_Pin */
  GPIO_InitStruct.Pin = TP28_Pin|TP25_Pin;
  GPIO_InitStruct.Mode = GPIO_MODE_INPUT;
  GPIO_InitStruct.Pull = GPIO_NOPULL;
  HAL_GPIO_Init(GPIOC, &GPIO_InitStruct);

  /*Configure GPIO pins : TP26_Pin TP27_Pin */
  GPIO_InitStruct.Pin = TP26_Pin|TP27_Pin;
  GPIO_InitStruct.Mode = GPIO_MODE_INPUT;
  GPIO_InitStruct.Pull = GPIO_NOPULL;
  HAL_GPIO_Init(GPIOA, &GPIO_InitStruct);

  /*Configure GPIO pins : LED4_Pin LED3_Pin */
  GPIO_InitStruct.Pin = LED4_Pin|LED3_Pin;
  GPIO_InitStruct.Mode = GPIO_MODE_OUTPUT_PP;
  GPIO_InitStruct.Pull = GPIO_NOPULL;
  GPIO_InitStruct.Speed = GPIO_SPEED_FREQ_LOW;
  HAL_GPIO_Init(GPIOC, &GPIO_InitStruct);

  /*Configure GPIO pins : LED2_Pin LED1_Pin */
  GPIO_InitStruct.Pin = LED2_Pin|LED1_Pin;
  GPIO_InitStruct.Mode = GPIO_MODE_OUTPUT_PP;
  GPIO_InitStruct.Pull = GPIO_NOPULL;
  GPIO_InitStruct.Speed = GPIO_SPEED_FREQ_LOW;
  HAL_GPIO_Init(GPIOE, &GPIO_InitStruct);

}

/* USER CODE BEGIN 4 */

void HAL_TIM_PeriodElapsedCallback(TIM_HandleTypeDef *htim)
{
	if(htim == &htim1) {
		status.sample_time += 1;
	}
}

void HAL_UART_TxCpltCallback(UART_HandleTypeDef *huart)
{
	if(huart==&huart3)
		HDLC_DMA_Send_Complete(huart);
}

static inline __attribute__((always_inline)) float computefilter(int chan, int idxs[])
{
	float v = 0.0;
	for(int i=0; i<FIR_LEN; i++) {
		// TODO check to see what the compiler-emitted assembly looks like.
		// if we're not using the fused multiply and add instruction, fix it.
		v += filter[i] * sensorbuffer[chan][idxs[i]];
	}
	return v;
}

static inline uint16_t min(uint16_t a, uint16_t b) {
	return (a<b) ? a : b;
}

static inline uint16_t max(uint16_t a, uint16_t b) {
	return (a>b) ? a : b;
}

// TODO move this into ITCM?
void HAL_ADC_ConvCpltCallback(ADC_HandleTypeDef *hadc)
{
	uint32_t now = status.sample_time;

	// Set up the variations on the copy loop
	uint16_t *buf;
	int cnt = 7;
	int offset = 0;
	int whichadc;
	int idxs[FIR_LEN] = {0};
	if(hadc==&hadc1) {
		buf = adc1_buffer;
		whichadc = 0;
		status.adc1_dmas++;
	} else if(hadc==&hadc2) {
		buf = adc2_buffer;
		offset = 7;
		whichadc = 1;
		status.adc2_dmas++;
	} else if(hadc==&hadc3){
		buf = adc3_buffer;
		cnt = 8;
		offset = 14;
		whichadc = 2;
		status.adc3_dmas++;
	} else {
		return;
	}

	int bufptr = bufferptrs[whichadc];

	uint16_t sendbuffer[DMASIZE];
	uint8_t TARGETCHANNEL = 100;

	// Copy the ADC buffers into the main circular buffer.
	for(int samp=0; samp<DMASIZE; samp++) {
		// each channel in there
		for(int i=0; i<cnt; i++) {
			int chan = offset+i;
			uint16_t v = 65535 - buf[samp*cnt+i];
			sensorbuffer[chan][(bufptr+samp) % BUFSIZE] = (float)(v);

			if(chan==TARGETCHANNEL) {
				sendbuffer[samp] = v;
			}

			if(collectstats) {
				stats[chan].min = min(stats[chan].min, v);
				stats[chan].max = max(stats[chan].max, v);
				stats[chan].count++;
				stats[chan].sum += v;
			}
		}
	}

	if(offset <= TARGETCHANNEL && TARGETCHANNEL < offset + cnt) {
		HDLC_Send_Frame(&huart3, 0x0A, (uint8_t*)sendbuffer, DMASIZE * sizeof(uint16_t));
	}

	// update bufferptrs to reflect new data
	bufptr = bufferptrs[whichadc] = (bufferptrs[whichadc] + DMASIZE) % BUFSIZE;

	// if we've been asked to stream a sensor out the serial port...
	if(0) {
		float buffer[1];
		buffer[0] = sensorbuffer[11][bufptr];
	    // read the DMASIZE values before bufptr
		HDLC_Send_Frame(&huart3, 0x0A, (uint8_t*)buffer, sizeof(buffer));
	}

	// TODO fill idxs with enough indexes to do two FIR/deriv calculations
	// for now-DMABUF/2 and now.
	for(int idx=0; idx<FIR_LEN; idx++) {
		// start from bufptr, which represents the next spot to write to
		// subtract one to get back to the most recent value
		// then go back by the length of the FIR filter
		// then add back the idx we want
		// that might be negative, so add BUFSIZE before doing %BUFSIZE.
		idxs[idx] = ((bufptr - 1 - FIR_LEN + idx) + BUFSIZE) % BUFSIZE;
	}
	// index of the middle value for the filter
	// division is right for odd numbers
	int mid = idxs[FIR_LEN/2];

#define INFDERIV(chan) { derivs[chan][derividxs[chan]] = INFINITY; derividxs[chan] = (1 + derividxs[chan]) % 3; }

	// We'll process the chunk we just got.
	for(int chan=offset; chan<offset+cnt; chan++) {
		if(conf[chan].hammer) {
			// Hammer

			// note that anywhere we skip this and don't compute the
			// derivative, we put +INF in for the current derivative.
			// this ensures that when we go to check to see if there
			// is a derivative peak, we don't use stale data.

			// This represents the "don't rapidly send multiple note-ons"
			// condition. At least MINCYCLESBETWEENNOTES has to pass before
			// we'll even look at the data again.
			if(state[chan].notesent) {
				// we've sent something recently.
				if(state[chan].notesent < now) {
					// no wrap situation
					if(state[chan].notesent < (now - MINCYCLESBETWEENNOTES)) {
						// enough time has passed.
						state[chan].notesent = 0;
					} else {
						// not enough time, ignore
						INFDERIV(chan);
						continue;
					}
				} else {
					// we've wrapped
					if((state[chan].notesent + MINCYCLESBETWEENNOTES) < now) {
						// also enough time as passed
						state[chan].notesent = 0;
					} else {
						// not enough time, ignore
						INFDERIV(chan);
						continue;
					}
				}
			}

			// This is the "the string can't sound until the hammer is close
			// enough" condition. If we're not close, don't look at the data.
			if(sensorbuffer[chan][mid] < conf[chan].minpos) {
				// hammer is too low
				INFDERIV(chan);
				continue;
			}

			// Ok, now we need the derivative
			float v = computefilter(chan, idxs);
			int didx = derividxs[chan]; // where we're putting our value
			derivs[chan][derividxs[chan]] = v;

			float derivold, derivmid, derivnew;
			derivnew = v;
			derivmid = derivs[chan][(didx + 3 - 1) % 3];
			derivold = derivs[chan][(didx + 3 - 2) % 3];

			// increment the spot we'll put the derivative
			derividxs[chan] = (1 + derividxs[chan]) % 3;

			// if derivmid is equal to either of the others, then we don't
			// actually trigger. but we're dealing with a float computed from
			// FIR_LEN input values. equality is unlikely.
			if(derivmid > 0.0 && derivmid > derivold && derivmid > derivnew) {
				state[chan].notesent = now;
				state[chan].sentval = v;
				state[chan].notesounding = 1;

				struct sensortrip msg;
				msg.chan = chan;
				msg.velocity = derivmid;
				HDLC_Send_Frame(&huart3, 0x08, (uint8_t*)&msg, sizeof(msg));
			}

		} else {
			// Key stick

			int hammerchan = conf[chan].hammerchan;

			// if the damper is up
			if(state[chan].damperup) {
				if(sensorbuffer[chan][mid] < conf[chan].offpos - 32) {
					// damper appears to have dropped back down.
					state[chan].damperup = 0;

					if(state[hammerchan].notesounding) {
						// our hammer has a note sounding. issue a note off.
						state[hammerchan].notesounding = 0;

						struct sensortrip msg;
						msg.chan = chan;
						// this is actually the derivative from a few
						// samples ago. good enough. key stick moves slowly.
						msg.velocity = computefilter(chan, idxs);
						HDLC_Send_Frame(&huart3, 0x08, (uint8_t*)&msg, sizeof(msg));
					}
				}
			} else {
				// damper is _down_
				if(sensorbuffer[chan][mid] > conf[chan].offpos + 32) {
					// damper appears to have been raised.
					state[chan].damperup = 1;

					// if we wanted to send "pre-lift" messages
					/*
					struct sensortrip msg;
					msg.chan = chan;
					msg.velocity = computefilter(chan, idxs);
					HDLC_Send_Frame(&huart3, 0x08, (uint8_t*)&msg, sizeof(msg));
					*/
				}
			}

/*
			if(state[hammerchan].notesounding) {
				if(sensorbuffer[chan][mid] < conf[chan].offpos) {
					// we've dropped low enough. we're dampening now,
					// so mark the note as stopped.
					state[hammerchan].notesounding = 0;
					state[hammerchan].damperup = 0;

					struct sensortrip msg;
					msg.chan = chan;
					// this is actually the derivative from a few
					// samples ago. good enough.
					msg.velocity = computefilter(chan, idxs);
					HDLC_Send_Frame(&huart3, 0x08, (uint8_t*)&msg, sizeof(msg));
				}
			}
*/
		}
	}
}

/* USER CODE END 4 */

void Error_Handler(void)
{
  /* USER CODE BEGIN Error_Handler_Debug */
  HDLC_Send_Frame(&huart3, 0x7F, "err", 3);

  // restart
  NVIC_SystemReset();

  /*
  __disable_irq();
  while (1)
  {
  }
  */

  /* USER CODE END Error_Handler_Debug */
}
